# PIC32MK0512GPL100 register map
Vendor: Microchip
Registers are 32-bit, read-write, no defined reset value unless marked. A register's access mark holds for its fields unless they carry their own. Addresses are absolute, and some are shared; only a register's first bit layout is shown; [hi:lo] are bit positions.

## OCMP10
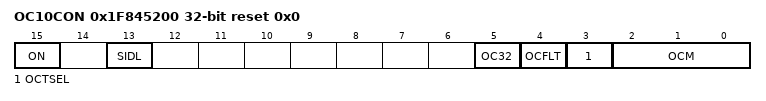
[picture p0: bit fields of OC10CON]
0x1F845200 OC10CON reset 0x0
  [15] ON, [13] SIDL, [5] OC32, [4] OCFLT ro, [3] OCTSEL, [2:0] OCM
0x1F845210 OC10R — (power-on value xxxxxxxxxxxxxxxxxxxxxxxxxxxxxxxx)
0x1F845220 OC10RS — (power-on value xxxxxxxxxxxxxxxxxxxxxxxxxxxxxxxx)

## OCMP11
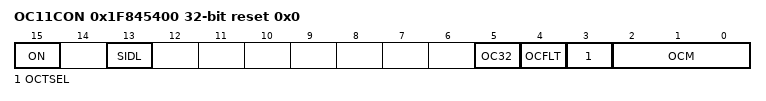
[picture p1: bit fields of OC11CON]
0x1F845400 OC11CON reset 0x0
  [15] ON, [13] SIDL, [5] OC32, [4] OCFLT ro, [3] OCTSEL, [2:0] OCM
0x1F845410 OC11R — (power-on value xxxxxxxxxxxxxxxxxxxxxxxxxxxxxxxx)
0x1F845420 OC11RS — (power-on value xxxxxxxxxxxxxxxxxxxxxxxxxxxxxxxx)

## OCMP12
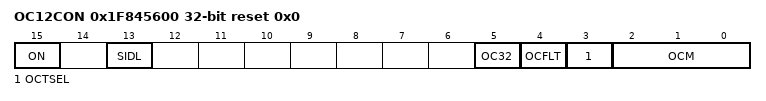
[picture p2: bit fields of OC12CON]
0x1F845600 OC12CON reset 0x0
  [15] ON, [13] SIDL, [5] OC32, [4] OCFLT ro, [3] OCTSEL, [2:0] OCM
0x1F845610 OC12R — (power-on value xxxxxxxxxxxxxxxxxxxxxxxxxxxxxxxx)
0x1F845620 OC12RS — (power-on value xxxxxxxxxxxxxxxxxxxxxxxxxxxxxxxx)

## OCMP13
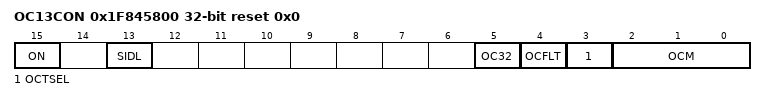
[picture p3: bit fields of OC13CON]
0x1F845800 OC13CON reset 0x0
  [15] ON, [13] SIDL, [5] OC32, [4] OCFLT ro, [3] OCTSEL, [2:0] OCM
0x1F845810 OC13R — (power-on value xxxxxxxxxxxxxxxxxxxxxxxxxxxxxxxx)
0x1F845820 OC13RS — (power-on value xxxxxxxxxxxxxxxxxxxxxxxxxxxxxxxx)

## OCMP14
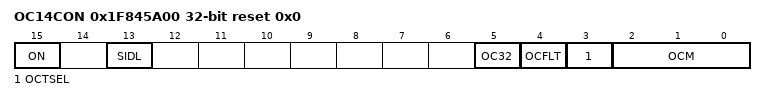
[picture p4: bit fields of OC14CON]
0x1F845A00 OC14CON reset 0x0
  [15] ON, [13] SIDL, [5] OC32, [4] OCFLT ro, [3] OCTSEL, [2:0] OCM
0x1F845A10 OC14R — (power-on value xxxxxxxxxxxxxxxxxxxxxxxxxxxxxxxx)
0x1F845A20 OC14RS — (power-on value xxxxxxxxxxxxxxxxxxxxxxxxxxxxxxxx)

## OCMP15
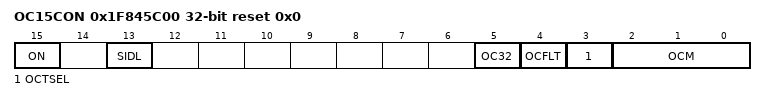
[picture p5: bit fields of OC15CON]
0x1F845C00 OC15CON reset 0x0
  [15] ON, [13] SIDL, [5] OC32, [4] OCFLT ro, [3] OCTSEL, [2:0] OCM
0x1F845C10 OC15R — (power-on value xxxxxxxxxxxxxxxxxxxxxxxxxxxxxxxx)
0x1F845C20 OC15RS — (power-on value xxxxxxxxxxxxxxxxxxxxxxxxxxxxxxxx)

## OCMP16
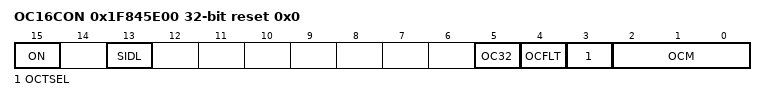
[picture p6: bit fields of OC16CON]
0x1F845E00 OC16CON reset 0x0
  [15] ON, [13] SIDL, [5] OC32, [4] OCFLT ro, [3] OCTSEL, [2:0] OCM
0x1F845E10 OC16R — (power-on value xxxxxxxxxxxxxxxxxxxxxxxxxxxxxxxx)
0x1F845E20 OC16RS — (power-on value xxxxxxxxxxxxxxxxxxxxxxxxxxxxxxxx)

## I2C3
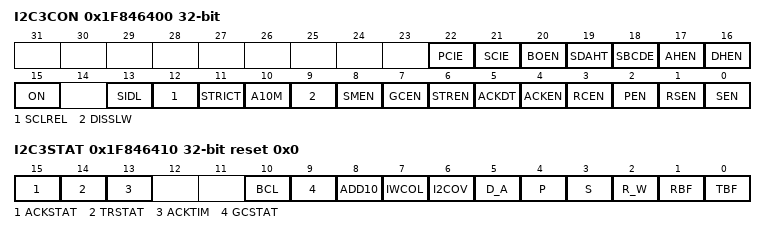
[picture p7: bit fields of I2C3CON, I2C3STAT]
0x1F846400 I2C3CON — (power-on value ---------00000000x01000000000000)
  [22] PCIE, [21] SCIE, [20] BOEN, [19] SDAHT, [18] SBCDE, [17] AHEN, [16] DHEN, [15] ON, [13] SIDL, [12] SCLREL, [11] STRICT, [10] A10M, [9] DISSLW, [8] SMEN, [7] GCEN, [6] STREN, [5] ACKDT, [4] ACKEN, [3] RCEN, [2] PEN, [1] RSEN, [0] SEN
0x1F846410 I2C3STAT reset 0x0
  [15] ACKSTAT ro
  [14] TRSTAT ro
  [13] ACKTIM ro
  [10] BCL — (can only be cleared)
  [9] GCSTAT ro
  [8] ADD10 ro
  [7] IWCOL — (can only be cleared)
  [6] I2COV — (can only be cleared)
  [5] D_A ro
  [4] P — (can only be cleared)
  [3] S — (can only be cleared)
  [2] R_W ro
  [1] RBF ro
  [0] TBF ro
0x1F846420 I2C3ADD reset 0x0
  [9:0] I2CADD
0x1F846430 I2C3MSK reset 0x0
  [9:0] I2CMSK
0x1F846440 I2C3BRG reset 0x0
  [15:0] I2CBRG
0x1F846450 I2C3TRN wo reset 0xFF
  [7:0] I2CTRN
0x1F846460 I2C3RCV ro reset 0x0
  [7:0] I2CRCV

## I2C4
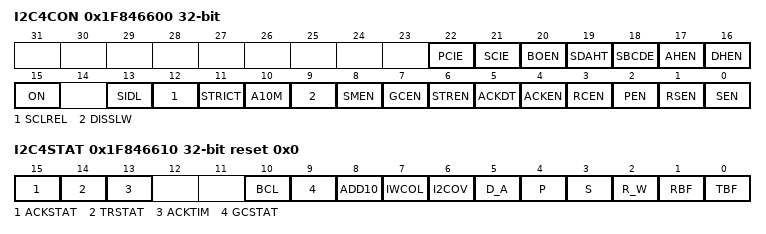
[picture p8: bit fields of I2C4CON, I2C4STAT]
0x1F846600 I2C4CON — (power-on value ---------00000000x01000000000000)
  [22] PCIE, [21] SCIE, [20] BOEN, [19] SDAHT, [18] SBCDE, [17] AHEN, [16] DHEN, [15] ON, [13] SIDL, [12] SCLREL, [11] STRICT, [10] A10M, [9] DISSLW, [8] SMEN, [7] GCEN, [6] STREN, [5] ACKDT, [4] ACKEN, [3] RCEN, [2] PEN, [1] RSEN, [0] SEN
0x1F846610 I2C4STAT reset 0x0
  [15] ACKSTAT ro
  [14] TRSTAT ro
  [13] ACKTIM ro
  [10] BCL — (can only be cleared)
  [9] GCSTAT ro
  [8] ADD10 ro
  [7] IWCOL — (can only be cleared)
  [6] I2COV — (can only be cleared)
  [5] D_A ro
  [4] P — (can only be cleared)
  [3] S — (can only be cleared)
  [2] R_W ro
  [1] RBF ro
  [0] TBF ro
0x1F846620 I2C4ADD reset 0x0
  [9:0] I2CADD
0x1F846630 I2C4MSK reset 0x0
  [9:0] I2CMSK
0x1F846640 I2C4BRG reset 0x0
  [15:0] I2CBRG
0x1F846650 I2C4TRN wo reset 0xFF
  [7:0] I2CTRN
0x1F846660 I2C4RCV ro reset 0x0
  [7:0] I2CRCV
